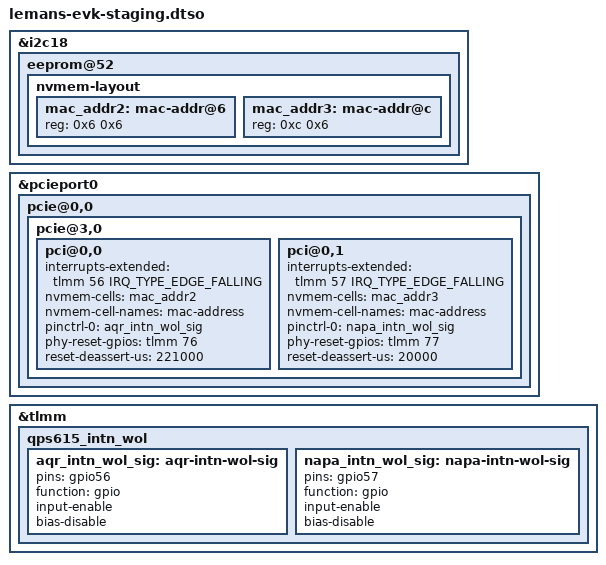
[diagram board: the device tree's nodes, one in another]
// SPDX-License-Identifier: BSD-3-Clause
/*
 * Copyright (c) Qualcomm Technologies, Inc. and/or its subsidiaries.
 */

/dts-v1/;
/plugin/;

#include <dt-bindings/gpio/gpio.h>
#include <dt-bindings/interrupt-controller/irq.h>

&i2c18 {
	eeprom@52 {
		nvmem-layout {
			mac_addr2: mac-addr@6 {
				reg = <0x6 0x6>;
			};
			mac_addr3: mac-addr@c {
				reg = <0xc 0x6>;
			};
		};
	};
};

&pcieport0 {
	pcie@0,0 {
		pcie@3,0 {
			pci@0,0 {
				interrupts-extended = <&tlmm 56 IRQ_TYPE_EDGE_FALLING>;
				interrupt-names = "wol_irq";
				nvmem-cells = <&mac_addr2>;
				nvmem-cell-names = "mac-address";
				pinctrl-names = "default";
				pinctrl-0 = <&aqr_intn_wol_sig>;
				phy-reset-gpios = <&tlmm 76 GPIO_ACTIVE_HIGH>;
				reset-deassert-us = <221000>;
			};

			pci@0,1 {
				interrupts-extended = <&tlmm 57 IRQ_TYPE_EDGE_FALLING>;
				interrupt-names = "wol_irq";
				nvmem-cells = <&mac_addr3>;
				nvmem-cell-names = "mac-address";
				pinctrl-names = "default";
				pinctrl-0 = <&napa_intn_wol_sig>;
				phy-reset-gpios = <&tlmm 77 GPIO_ACTIVE_HIGH>;
				reset-deassert-us = <20000>;
			};
		};
	};
};

&tlmm {
	qps615_intn_wol {
		aqr_intn_wol_sig: aqr-intn-wol-sig {
			pins = "gpio56";
			function = "gpio";
			input-enable;
			bias-disable;
		};
		napa_intn_wol_sig: napa-intn-wol-sig {
			pins = "gpio57";
			function = "gpio";
			input-enable;
			bias-disable;
		};
	};
};
